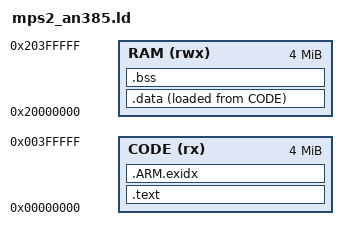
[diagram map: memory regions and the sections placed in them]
/* QEMU mps2-an385 (Cortex-M3): code in ZBT SSRAM1, data in SSRAM2. */
ENTRY(reset_handler)

MEMORY
{
    CODE (rx) : ORIGIN = 0x00000000, LENGTH = 4M
    RAM (rwx) : ORIGIN = 0x20000000, LENGTH = 4M
}

SECTIONS
{
    .text : { KEEP(*(.vectors)) *(.text*) *(.rodata*) . = ALIGN(4); } > CODE
    .ARM.exidx : { *(.ARM.exidx*) } > CODE
    .data : { _sdata = .; *(.data*) . = ALIGN(4); _edata = .; } > RAM AT > CODE
    _sidata = LOADADDR(.data);
    .bss (NOLOAD) : { _sbss = .; *(.bss*) *(COMMON) . = ALIGN(4); _ebss = .; } > RAM
    _estack = ORIGIN(RAM) + 64K;
}
